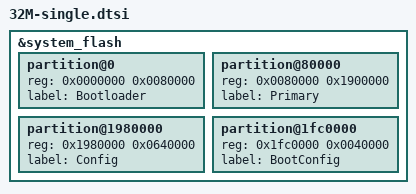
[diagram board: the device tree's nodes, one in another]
&system_flash {
	partition@0 {
		/* 512k */
		reg = <0x0000000 0x0080000>;
		label = "Bootloader";
	};
	partition@80000 {
		/* 25M */
		reg = <0x0080000 0x1900000>;
		label = "Primary";
	};
	partition@1980000 {
		/* 6.4M */
		reg = <0x1980000 0x0640000>;
		label = "Config";
	};
	partition@1fc0000 {
		/* 256k */
		reg = <0x1fc0000 0x0040000>;
		label = "BootConfig";
	};
};
